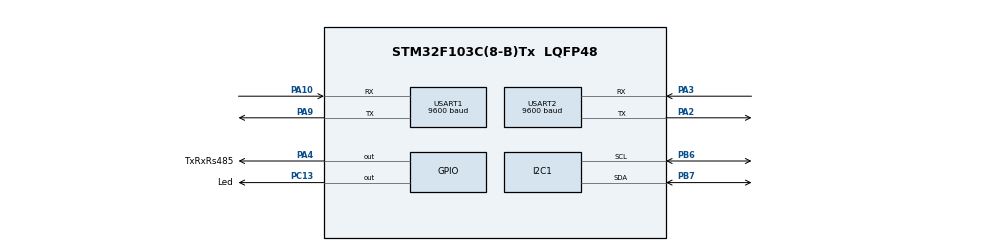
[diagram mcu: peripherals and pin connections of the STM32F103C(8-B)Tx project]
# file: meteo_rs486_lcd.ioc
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IWDG.Prescaler=IWDG_PRESCALER_128
Mcu.Family=STM32F1
Mcu.Name=STM32F103C(8-B)Tx
Mcu.Package=LQFP48
NVIC.PriorityGroup=NVIC_PRIORITYGROUP_4
NVIC.TIM3_IRQn=true\:0\:0\:false\:false\:true\:true\:true\:true
NVIC.TIM4_IRQn=true\:0\:0\:false\:false\:true\:true\:true\:true
NVIC.USART2_IRQn=true\:0\:0\:false\:false\:true\:true\:true\:true
PA10.Mode=Asynchronous
PA10.Signal=USART1_RX
PA13.Mode=Serial_Wire
PA13.Signal=SYS_JTMS-SWDIO
PA14.Mode=Serial_Wire
PA14.Signal=SYS_JTCK-SWCLK
PA2.Mode=Asynchronous
PA2.Signal=USART2_TX
PA3.Mode=Asynchronous
PA3.Signal=USART2_RX
PA4.GPIO_Label=TxRxRs485
PA4.Signal=GPIO_Output
PA9.Mode=Asynchronous
PA9.Signal=USART1_TX
PB6.Mode=I2C
PB6.Signal=I2C1_SCL
PB7.Mode=I2C
PB7.Signal=I2C1_SDA
PC13-TAMPER-RTC.GPIO_Label=Led
PC13-TAMPER-RTC.Signal=GPIO_Output
PD0-OSC_IN.Mode=HSE-External-Oscillator
PD0-OSC_IN.Signal=RCC_OSC_IN
PD1-OSC_OUT.Mode=HSE-External-Oscillator
PD1-OSC_OUT.Signal=RCC_OSC_OUT
ProjectManager.HeapSize=0x200
ProjectManager.StackSize=0x400
ProjectManager.TargetToolchain=STM32CubeIDE
RCC.AHBCLKDivider=RCC_SYSCLK_DIV2
RCC.AHBFreq_Value=8000000
RCC.APB1Freq_Value=8000000
RCC.APB1TimFreq_Value=8000000
RCC.APB2Freq_Value=8000000
RCC.APB2TimFreq_Value=8000000
RCC.HCLKFreq_Value=8000000
RCC.PLLSourceVirtual=RCC_PLLSOURCE_HSE
RCC.SYSCLKFreq_VALUE=16000000
RCC.SYSCLKSource=RCC_SYSCLKSOURCE_PLLCLK
RCC.USBFreq_Value=16000000
TIM3.Channel-Output\ Compare1\ No\ Output=TIM_CHANNEL_1
TIM3.Period=5
TIM3.Prescaler=79
TIM4.Channel-Output\ Compare1\ No\ Output=TIM_CHANNEL_1
TIM4.Period=6999
TIM4.Prescaler=6999
USART1.BaudRate=9600
USART1.VirtualMode=VM_ASYNC
USART2.BaudRate=9600
USART2.VirtualMode=VM_ASYNC
VP_IWDG_VS_IWDG.Mode=IWDG_Activate
VP_TIM3_VS_ClockSourceINT.Mode=Internal
VP_TIM3_VS_no_output1.Mode=Output Compare1 No Output
VP_TIM4_VS_ClockSourceINT.Mode=Internal
VP_TIM4_VS_no_output1.Mode=Output Compare1 No Output
board=custom

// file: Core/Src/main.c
/* USER CODE BEGIN Header */
/**
  ******************************************************************************
  * @file           : main.c
  * @brief          : Main program body
  ******************************************************************************
  * @attention
  *
  * Copyright (c) 2023 STMicroelectronics.
  * All rights reserved.
  *
  * This software is licensed under terms that can be found in the LICENSE file
  * in the root directory of this software component.
  * If no LICENSE file comes with this software, it is provided AS-IS.
  *
  ******************************************************************************
  */
/* USER CODE END Header */
#include "main.h"
#include "i2c.h"
#include "iwdg.h"
#include "tim.h"
#include "usart.h"
#include "gpio.h"

/* USER CODE BEGIN Includes */
#include "loop.h"
#include "setup.h"
/* USER CODE END Includes */

void SystemClock_Config(void);

int main(void)
{

  /* MCU Configuration--------------------------------------------------------*/

  /* Reset of all peripherals, Initializes the Flash interface and the Systick. */
  HAL_Init();

  /* Configure the system clock */
  SystemClock_Config();

  /* Initialize all configured peripherals */
  MX_GPIO_Init();
  MX_TIM4_Init();
  MX_USART1_UART_Init();
  MX_USART2_UART_Init();
  MX_TIM3_Init();
  MX_I2C1_Init();
  MX_IWDG_Init();

  /* Infinite loop */
  /* USER CODE BEGIN WHILE */

  Init();
  Loop();

  while (1)
  {
    /* USER CODE END WHILE */

  }
}

void SystemClock_Config(void)
{
  LL_FLASH_SetLatency(LL_FLASH_LATENCY_0);
  while(LL_FLASH_GetLatency()!= LL_FLASH_LATENCY_0)
  {
  }
  LL_RCC_HSE_Enable();

   /* Wait till HSE is ready */
  while(LL_RCC_HSE_IsReady() != 1)
  {

  }
  LL_RCC_LSI_Enable();

   /* Wait till LSI is ready */
  while(LL_RCC_LSI_IsReady() != 1)
  {

  }
  LL_RCC_PLL_ConfigDomain_SYS(LL_RCC_PLLSOURCE_HSE_DIV_1, LL_RCC_PLL_MUL_2);
  LL_RCC_PLL_Enable();

   /* Wait till PLL is ready */
  while(LL_RCC_PLL_IsReady() != 1)
  {

  }
  LL_RCC_SetAHBPrescaler(LL_RCC_SYSCLK_DIV_2);
  LL_RCC_SetAPB1Prescaler(LL_RCC_APB1_DIV_1);
  LL_RCC_SetAPB2Prescaler(LL_RCC_APB2_DIV_1);
  LL_RCC_SetSysClkSource(LL_RCC_SYS_CLKSOURCE_PLL);

   /* Wait till System clock is ready */
  while(LL_RCC_GetSysClkSource() != LL_RCC_SYS_CLKSOURCE_STATUS_PLL)
  {

  }
  LL_SetSystemCoreClock(8000000);

   /* Update the time base */
  if (HAL_InitTick (TICK_INT_PRIORITY) != HAL_OK)
  {
    Error_Handler();
  }
}

void Error_Handler(void)
{
  __disable_irq();
  while (1)
  {
  }
}
